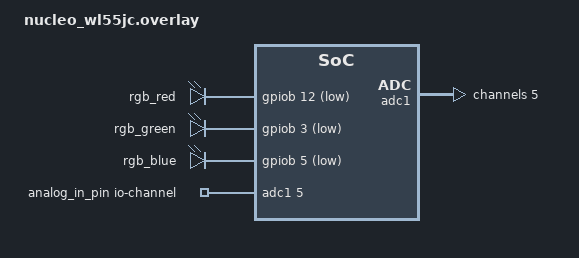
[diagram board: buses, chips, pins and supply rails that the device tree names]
#include <zephyr/dt-bindings/adc/adc.h>
#include <zephyr/dt-bindings/gpio/gpio.h>

/*------------CONFIGURACIÓN DEL ADC------------*/

&adc1 {
    status = "okay";
    #address-cells = <1>;
    #size-cells = <0>;

    channel@5 {
        reg = <5>;
        zephyr,gain = "ADC_GAIN_1";
        zephyr,reference = "ADC_REF_INTERNAL";
        zephyr,acquisition-time = <ADC_ACQ_TIME_DEFAULT>;
        zephyr,resolution = <12>;
    };
};

/*------------DiviceTree------------*/

/ {
    rgb_leds {
        compatible = "gpio-leds";

        rgb_red: rgb_red {
            gpios = <&gpiob 12 GPIO_ACTIVE_LOW>; // D2 
        };

        rgb_green: rgb_green {
            gpios = <&gpiob 3 GPIO_ACTIVE_LOW>; // D3
        };

        rgb_blue: rgb_blue {
            gpios = <&gpiob 5 GPIO_ACTIVE_LOW>; // D4
        };
    };

    /*------------CONFIGURACIÓN DEL SENSOR ANALÓGICO------------*/

    analog_in_pin: zephyr,user {
        io-channels = <&adc1 5>;
    };

    /*------------ ALIASES ------------ */

    aliases {
        analog-in-pin = &analog_in_pin;

        red-led = &rgb_red;
        green-led = &rgb_green;
        blue-led = &rgb_blue;
    };
};
